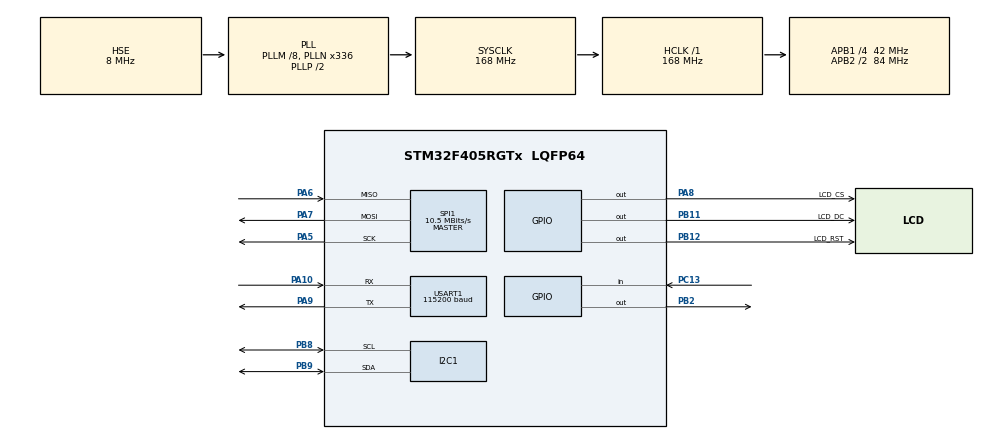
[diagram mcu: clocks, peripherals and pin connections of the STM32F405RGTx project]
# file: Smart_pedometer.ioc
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Dma.I2C1_RX.4.Direction=DMA_PERIPH_TO_MEMORY
Dma.I2C1_RX.4.FIFOMode=DMA_FIFOMODE_DISABLE
Dma.I2C1_RX.4.Instance=DMA1_Stream5
Dma.I2C1_RX.4.MemDataAlignment=DMA_MDATAALIGN_BYTE
Dma.I2C1_RX.4.MemInc=DMA_MINC_ENABLE
Dma.I2C1_RX.4.Mode=DMA_NORMAL
Dma.I2C1_RX.4.PeriphDataAlignment=DMA_PDATAALIGN_BYTE
Dma.I2C1_RX.4.PeriphInc=DMA_PINC_DISABLE
Dma.I2C1_RX.4.Priority=DMA_PRIORITY_LOW
Dma.I2C1_TX.5.Direction=DMA_MEMORY_TO_PERIPH
Dma.I2C1_TX.5.FIFOMode=DMA_FIFOMODE_DISABLE
Dma.I2C1_TX.5.Instance=DMA1_Stream6
Dma.I2C1_TX.5.MemDataAlignment=DMA_MDATAALIGN_BYTE
Dma.I2C1_TX.5.MemInc=DMA_MINC_ENABLE
Dma.I2C1_TX.5.Mode=DMA_NORMAL
Dma.I2C1_TX.5.PeriphDataAlignment=DMA_PDATAALIGN_BYTE
Dma.I2C1_TX.5.PeriphInc=DMA_PINC_DISABLE
Dma.I2C1_TX.5.Priority=DMA_PRIORITY_LOW
Dma.Request0=SPI1_RX
Dma.Request1=SPI1_TX
Dma.Request2=USART1_RX
Dma.Request3=USART1_TX
Dma.Request4=I2C1_RX
Dma.Request5=I2C1_TX
Dma.SPI1_RX.0.Direction=DMA_PERIPH_TO_MEMORY
Dma.SPI1_RX.0.FIFOMode=DMA_FIFOMODE_DISABLE
Dma.SPI1_RX.0.Instance=DMA2_Stream0
Dma.SPI1_RX.0.MemDataAlignment=DMA_MDATAALIGN_BYTE
Dma.SPI1_RX.0.MemInc=DMA_MINC_ENABLE
Dma.SPI1_RX.0.Mode=DMA_NORMAL
Dma.SPI1_RX.0.PeriphDataAlignment=DMA_PDATAALIGN_BYTE
Dma.SPI1_RX.0.PeriphInc=DMA_PINC_DISABLE
Dma.SPI1_RX.0.Priority=DMA_PRIORITY_LOW
Dma.SPI1_TX.1.Direction=DMA_MEMORY_TO_PERIPH
Dma.SPI1_TX.1.FIFOMode=DMA_FIFOMODE_DISABLE
Dma.SPI1_TX.1.Instance=DMA2_Stream3
Dma.SPI1_TX.1.MemDataAlignment=DMA_MDATAALIGN_BYTE
Dma.SPI1_TX.1.MemInc=DMA_MINC_ENABLE
Dma.SPI1_TX.1.Mode=DMA_NORMAL
Dma.SPI1_TX.1.PeriphDataAlignment=DMA_PDATAALIGN_BYTE
Dma.SPI1_TX.1.PeriphInc=DMA_PINC_DISABLE
Dma.SPI1_TX.1.Priority=DMA_PRIORITY_LOW
Dma.USART1_RX.2.Direction=DMA_PERIPH_TO_MEMORY
Dma.USART1_RX.2.FIFOMode=DMA_FIFOMODE_DISABLE
Dma.USART1_RX.2.Instance=DMA2_Stream2
Dma.USART1_RX.2.MemDataAlignment=DMA_MDATAALIGN_BYTE
Dma.USART1_RX.2.MemInc=DMA_MINC_ENABLE
Dma.USART1_RX.2.Mode=DMA_CIRCULAR
Dma.USART1_RX.2.PeriphDataAlignment=DMA_PDATAALIGN_BYTE
Dma.USART1_RX.2.PeriphInc=DMA_PINC_DISABLE
Dma.USART1_RX.2.Priority=DMA_PRIORITY_LOW
Dma.USART1_TX.3.Direction=DMA_MEMORY_TO_PERIPH
Dma.USART1_TX.3.FIFOMode=DMA_FIFOMODE_DISABLE
Dma.USART1_TX.3.Instance=DMA2_Stream7
Dma.USART1_TX.3.MemDataAlignment=DMA_MDATAALIGN_BYTE
Dma.USART1_TX.3.MemInc=DMA_MINC_ENABLE
Dma.USART1_TX.3.Mode=DMA_NORMAL
Dma.USART1_TX.3.PeriphDataAlignment=DMA_PDATAALIGN_BYTE
Dma.USART1_TX.3.PeriphInc=DMA_PINC_DISABLE
Dma.USART1_TX.3.Priority=DMA_PRIORITY_LOW
FREERTOS.Mutexes01=IIC_LOCK,Static,IIC_LOCKControlBlock,Available;SPI1_LOCK,Static,SPI1_LOCKControlBlock,Available;UART1_LOCK,Static,UART1_LOCKControlBlock,Available
FREERTOS.Queues01=KEY_EVT_Q,8,key_event_msg_t,0,Static,KEY_EVT_QBuffer,KEY_EVT_QControlBlock;UART_EVT_Q,4,dev_uart_t*,0,Static,UART_EVT_QBuffer,UART_EVT_QControlBlock
FREERTOS.Tasks01=defaultTask,8,128,StartDefaultTask,As weak,NULL,Static,defaultTaskBuffer,defaultTaskControlBlock;KEY_T,48,128,Task_Key_Scan,As weak,NULL,KEY_TBuffer,KEY_TControlBlock;KEY_CMD_T,40,256,Task_Key_Cmd,As weak,NULL,KEY_CMD_TBuffer,KEY_CMD_TControlBlock;LVGL_T,32,2048,Task_LVGL,As weak,NULL,LVGL_TBuffer,LVGL_TControlBlock;UART_T,24,256,Task_UART,As weak,NULL,UART_TBuffer,UART_TControlBlock
FREERTOS.configMINIMAL_STACK_SIZE=64
I2C1.I2C_Mode=I2C_Fast
Mcu.Family=STM32F4
Mcu.Name=STM32F405RGTx
Mcu.Package=LQFP64
NVIC.DMA1_Stream5_IRQn=true\:5\:0\:false\:false\:true\:true\:false\:true\:true
NVIC.DMA1_Stream6_IRQn=true\:5\:0\:false\:false\:true\:true\:false\:true\:true
NVIC.DMA2_Stream0_IRQn=true\:5\:0\:false\:false\:true\:true\:false\:true\:true
NVIC.DMA2_Stream2_IRQn=true\:5\:0\:false\:false\:true\:true\:false\:true\:true
NVIC.DMA2_Stream3_IRQn=true\:5\:0\:false\:false\:true\:true\:false\:true\:true
NVIC.DMA2_Stream7_IRQn=true\:5\:0\:false\:false\:true\:true\:false\:true\:true
NVIC.I2C1_ER_IRQn=true\:5\:0\:false\:false\:true\:true\:true\:true\:true
NVIC.I2C1_EV_IRQn=true\:5\:0\:false\:false\:true\:true\:true\:true\:true
NVIC.PriorityGroup=NVIC_PRIORITYGROUP_4
NVIC.SPI1_IRQn=true\:5\:0\:false\:false\:true\:true\:true\:true\:true
NVIC.TIM4_IRQn=true\:15\:0\:false\:false\:true\:false\:false\:true\:true
NVIC.TimeBase=TIM4_IRQn
NVIC.TimeBaseIP=TIM4
NVIC.USART1_IRQn=true\:5\:0\:false\:false\:true\:true\:true\:true\:true
PA10.Mode=Asynchronous
PA10.Signal=USART1_RX
PA13.Mode=Serial_Wire
PA13.Signal=SYS_JTMS-SWDIO
PA14.Mode=Serial_Wire
PA14.Signal=SYS_JTCK-SWCLK
PA5.Mode=Full_Duplex_Master
PA5.Signal=SPI1_SCK
PA6.Mode=Full_Duplex_Master
PA6.Signal=SPI1_MISO
PA7.Mode=Full_Duplex_Master
PA7.Signal=SPI1_MOSI
PA8.GPIO_Label=LCD_CS
PA8.GPIO_PuPd=GPIO_NOPULL
PA8.GPIO_Speed=GPIO_SPEED_FREQ_HIGH
PA8.PinState=GPIO_PIN_SET
PA8.Signal=GPIO_Output
PA9.Mode=Asynchronous
PA9.Signal=USART1_TX
PB11.GPIO_Label=LCD_DC
PB11.GPIO_ModeDefaultOutputPP=GPIO_MODE_OUTPUT_PP
PB11.GPIO_PuPd=GPIO_NOPULL
PB11.GPIO_Speed=GPIO_SPEED_FREQ_HIGH
PB11.PinState=GPIO_PIN_RESET
PB11.Signal=GPIO_Output
PB12.GPIO_Label=LCD_RST
PB12.GPIO_PuPd=GPIO_NOPULL
PB12.GPIO_Speed=GPIO_SPEED_FREQ_HIGH
PB12.PinState=GPIO_PIN_SET
PB12.Signal=GPIO_Output
PB2.GPIO_PuPd=GPIO_PULLDOWN
PB2.PinState=GPIO_PIN_RESET
PB2.Signal=GPIO_Output
PB8.Mode=I2C
PB8.Signal=I2C1_SCL
PB9.Mode=I2C
PB9.Signal=I2C1_SDA
PC13-ANTI_TAMP.GPIO_Mode=GPIO_MODE_INPUT
PC13-ANTI_TAMP.GPIO_PuPd=GPIO_PULLDOWN
PC13-ANTI_TAMP.Signal=GPIO_Input
PH0-OSC_IN.Mode=HSE-External-Oscillator
PH0-OSC_IN.Signal=RCC_OSC_IN
PH1-OSC_OUT.Mode=HSE-External-Oscillator
PH1-OSC_OUT.Signal=RCC_OSC_OUT
ProjectManager.HeapSize=0x200
ProjectManager.StackSize=0x400
ProjectManager.TargetToolchain=CMake
RCC.AHBFreq_Value=168000000
RCC.APB1CLKDivider=RCC_HCLK_DIV4
RCC.APB1Freq_Value=42000000
RCC.APB1TimFreq_Value=84000000
RCC.APB2CLKDivider=RCC_HCLK_DIV2
RCC.APB2Freq_Value=84000000
RCC.APB2TimFreq_Value=168000000
RCC.CortexFreq_Value=168000000
RCC.HCLKFreq_Value=168000000
RCC.HSE_VALUE=8000000
RCC.HSI_VALUE=16000000
RCC.LSE_VALUE=32768
RCC.PLLM=8
RCC.PLLN=336
RCC.PLLP=RCC_PLLP_DIV2
RCC.PLLQ=7
RCC.PLLSourceVirtual=RCC_PLLSOURCE_HSE
RCC.SYSCLKFreq_VALUE=168000000
RCC.SYSCLKSource=RCC_SYSCLKSOURCE_PLLCLK
RCC.VCOOutputFreq_Value=336000000
SPI1.BaudRatePrescaler=SPI_BAUDRATEPRESCALER_8
SPI1.CalculateBaudRate=10.5 MBits/s
SPI1.Direction=SPI_DIRECTION_2LINES
SPI1.Mode=SPI_MODE_MASTER
SPI1.VirtualType=VM_MASTER
USART1.BaudRate=115200
USART1.VirtualMode=VM_ASYNC
VP_CRC_VS_CRC.Mode=CRC_Activate
VP_FREERTOS_VS_CMSIS_V2.Mode=CMSIS_V2
VP_SYS_VS_tim4.Mode=TIM4
board=custom

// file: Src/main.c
/* USER CODE BEGIN Header */
/**
  ******************************************************************************
  * @file           : main.c
  * @brief          : Main program body
  ******************************************************************************
  * @attention
  *
  * Copyright (c) 2026 STMicroelectronics.
  * All rights reserved.
  *
  * This software is licensed under terms that can be found in the LICENSE file
  * in the root directory of this software component.
  * If no LICENSE file comes with this software, it is provided AS-IS.
  *
  ******************************************************************************
  */
/* USER CODE END Header */
#include "main.h"
#include "cmsis_os.h"
#include "crc.h"
#include "dma.h"
#include "i2c.h"
#include "spi.h"
#include "usart.h"
#include "gpio.h"

void SystemClock_Config(void);
void MX_FREERTOS_Init(void);

int main(void)
{

  /* MCU Configuration--------------------------------------------------------*/

  /* Reset of all peripherals, Initializes the Flash interface and the Systick. */
  HAL_Init();

  /* Configure the system clock */
  SystemClock_Config();

  /* Initialize all configured peripherals */
  MX_GPIO_Init();
  MX_DMA_Init();
  MX_CRC_Init();
  MX_I2C1_Init();
  MX_SPI1_Init();
  MX_USART1_UART_Init();

  /* Init scheduler */
  osKernelInitialize();  /* Call init function for freertos objects (in cmsis_os2.c) */
  MX_FREERTOS_Init();

  /* Start scheduler */
  osKernelStart();

  /* We should never get here as control is now taken by the scheduler */

  /* Infinite loop */
  while (1)
  {

  }
}

void SystemClock_Config(void)
{
  RCC_OscInitTypeDef RCC_OscInitStruct = {0};
  RCC_ClkInitTypeDef RCC_ClkInitStruct = {0};

  /** Configure the main internal regulator output voltage
  */
  __HAL_RCC_PWR_CLK_ENABLE();
  __HAL_PWR_VOLTAGESCALING_CONFIG(PWR_REGULATOR_VOLTAGE_SCALE1);

  /** Initializes the RCC Oscillators according to the specified parameters
  * in the RCC_OscInitTypeDef structure.
  */
  RCC_OscInitStruct.OscillatorType = RCC_OSCILLATORTYPE_HSE;
  RCC_OscInitStruct.HSEState = RCC_HSE_ON;
  RCC_OscInitStruct.PLL.PLLState = RCC_PLL_ON;
  RCC_OscInitStruct.PLL.PLLSource = RCC_PLLSOURCE_HSE;
  RCC_OscInitStruct.PLL.PLLM = 8;
  RCC_OscInitStruct.PLL.PLLN = 336;
  RCC_OscInitStruct.PLL.PLLP = RCC_PLLP_DIV2;
  RCC_OscInitStruct.PLL.PLLQ = 7;
  if (HAL_RCC_OscConfig(&RCC_OscInitStruct) != HAL_OK)
  {
    Error_Handler();
  }

  /** Initializes the CPU, AHB and APB buses clocks
  */
  RCC_ClkInitStruct.ClockType = RCC_CLOCKTYPE_HCLK|RCC_CLOCKTYPE_SYSCLK
                              |RCC_CLOCKTYPE_PCLK1|RCC_CLOCKTYPE_PCLK2;
  RCC_ClkInitStruct.SYSCLKSource = RCC_SYSCLKSOURCE_PLLCLK;
  RCC_ClkInitStruct.AHBCLKDivider = RCC_SYSCLK_DIV1;
  RCC_ClkInitStruct.APB1CLKDivider = RCC_HCLK_DIV4;
  RCC_ClkInitStruct.APB2CLKDivider = RCC_HCLK_DIV2;

  if (HAL_RCC_ClockConfig(&RCC_ClkInitStruct, FLASH_LATENCY_5) != HAL_OK)
  {
    Error_Handler();
  }
}

void HAL_TIM_PeriodElapsedCallback(TIM_HandleTypeDef *htim)
{
  if (htim->Instance == TIM4)
  {
    HAL_IncTick();
  }
}

void Error_Handler(void)
{
  __disable_irq();
  while (1)
  {
  }
}

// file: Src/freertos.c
/* USER CODE BEGIN Header */
/**
  ******************************************************************************
  * File Name          : freertos.c
  * Description        : Code for freertos applications
  ******************************************************************************
  * @attention
  *
  * Copyright (c) 2026 STMicroelectronics.
  * All rights reserved.
  *
  * This software is licensed under terms that can be found in the LICENSE file
  * in the root directory of this software component.
  * If no LICENSE file comes with this software, it is provided AS-IS.
  *
  ******************************************************************************
  */
/* USER CODE END Header */

#include "FreeRTOS.h"
#include "task.h"
#include "main.h"
#include "cmsis_os.h"

/* USER CODE BEGIN Includes */
#include "osal_types.h"
#include "bsp_iic.h"
#include "bsp_spi.h"
#include "dev_spi.h"
#include "dev_iic.h"
/* USER CODE END Includes */

typedef StaticTask_t osStaticThreadDef_t;
typedef StaticQueue_t osStaticMessageQDef_t;
typedef StaticSemaphore_t osStaticMutexDef_t;

/* Definitions for defaultTask */
osThreadId_t defaultTaskHandle;
uint32_t defaultTaskBuffer[ 128 ];
osStaticThreadDef_t defaultTaskControlBlock;
const osThreadAttr_t defaultTask_attributes = {
  .name = "defaultTask",
  .cb_mem = &defaultTaskControlBlock,
  .cb_size = sizeof(defaultTaskControlBlock),
  .stack_mem = &defaultTaskBuffer[0],
  .stack_size = sizeof(defaultTaskBuffer),
  .priority = (osPriority_t) osPriorityLow,
};
/* Definitions for KEY_T */
osThreadId_t KEY_THandle;
const osThreadAttr_t KEY_T_attributes = {
  .name = "KEY_T",
  .stack_size = 128 * 4,
  .priority = (osPriority_t) osPriorityRealtime,
};
/* Definitions for KEY_CMD_T */
osThreadId_t KEY_CMD_THandle;
const osThreadAttr_t KEY_CMD_T_attributes = {
  .name = "KEY_CMD_T",
  .stack_size = 256 * 4,
  .priority = (osPriority_t) osPriorityHigh,
};
/* Definitions for LVGL_T */
osThreadId_t LVGL_THandle;
const osThreadAttr_t LVGL_T_attributes = {
  .name = "LVGL_T",
  .stack_size = 2048 * 4,
  .priority = (osPriority_t) osPriorityAboveNormal,
};
/* Definitions for UART_T */
osThreadId_t UART_THandle;
const osThreadAttr_t UART_T_attributes = {
  .name = "UART_T",
  .stack_size = 256 * 4,
  .priority = (osPriority_t) osPriorityNormal,
};
/* Definitions for KEY_EVT_Q */
osMessageQueueId_t KEY_EVT_QHandle;
uint8_t KEY_EVT_QBuffer[ 8 * sizeof( key_event_msg_t ) ];
osStaticMessageQDef_t KEY_EVT_QControlBlock;
const osMessageQueueAttr_t KEY_EVT_Q_attributes = {
  .name = "KEY_EVT_Q",
  .cb_mem = &KEY_EVT_QControlBlock,
  .cb_size = sizeof(KEY_EVT_QControlBlock),
  .mq_mem = &KEY_EVT_QBuffer,
  .mq_size = sizeof(KEY_EVT_QBuffer)
};
/* Definitions for UART_EVT_Q */
osMessageQueueId_t UART_EVT_QHandle;
uint8_t UART_EVT_QBuffer[ 4 * sizeof( dev_uart_t* ) ];
osStaticMessageQDef_t UART_EVT_QControlBlock;
const osMessageQueueAttr_t UART_EVT_Q_attributes = {
  .name = "UART_EVT_Q",
  .cb_mem = &UART_EVT_QControlBlock,
  .cb_size = sizeof(UART_EVT_QControlBlock),
  .mq_mem = &UART_EVT_QBuffer,
  .mq_size = sizeof(UART_EVT_QBuffer)
};
/* Definitions for IIC_LOCK */
osMutexId_t IIC_LOCKHandle;
osStaticMutexDef_t IIC_LOCKControlBlock;
const osMutexAttr_t IIC_LOCK_attributes = {
  .name = "IIC_LOCK",
  .cb_mem = &IIC_LOCKControlBlock,
  .cb_size = sizeof(IIC_LOCKControlBlock),
};
/* Definitions for SPI1_LOCK */
osMutexId_t SPI1_LOCKHandle;
osStaticMutexDef_t SPI1_LOCKControlBlock;
const osMutexAttr_t SPI1_LOCK_attributes = {
  .name = "SPI1_LOCK",
  .cb_mem = &SPI1_LOCKControlBlock,
  .cb_size = sizeof(SPI1_LOCKControlBlock),
};
/* Definitions for UART1_LOCK */
osMutexId_t UART1_LOCKHandle;
osStaticMutexDef_t UART1_LOCKControlBlock;
const osMutexAttr_t UART1_LOCK_attributes = {
  .name = "UART1_LOCK",
  .cb_mem = &UART1_LOCKControlBlock,
  .cb_size = sizeof(UART1_LOCKControlBlock),
};

void StartDefaultTask(void *argument);
void Task_Key_Scan(void *argument);
void Task_Key_Cmd(void *argument);
void Task_LVGL(void *argument);
void Task_UART(void *argument);

void MX_FREERTOS_Init(void); /* (MISRA C 2004 rule 8.1) */

void MX_FREERTOS_Init(void) {
  /* USER CODE BEGIN Init */
  Svc_Key_Logic_Init();   /* 以当前键电平作为"已确认"初态，避免上电误报 DOWN */
  /* USER CODE END Init */
  /* Create the mutex(es) */
  /* creation of IIC_LOCK */
  IIC_LOCKHandle = osMutexNew(&IIC_LOCK_attributes);

  /* creation of SPI1_LOCK */
  SPI1_LOCKHandle = osMutexNew(&SPI1_LOCK_attributes);

  /* creation of UART1_LOCK */
  UART1_LOCKHandle = osMutexNew(&UART1_LOCK_attributes);

  /* USER CODE BEGIN RTOS_MUTEX */
  /* 要互斥量的 BSP 初始化必须在这里：CubeMX 刚把这几把锁建出来，
   早一段（Init）句柄还是 NULL，会被 BSP_xxx_Init() 判成 ERR_STATE。
   设备层的虚拟外设跟在对应 BSP 总线之后：Dev_SPI / Dev_IIC 各自认领
   SPI1 / IIC 这把锁，并把片选、换速、超时这些"总线使用规则"接在
   BSP_SPI / BSP_IIC 之上。 */
  BSP_IIC_Init();
  Dev_IIC_Init(&dev_iic1);
  BSP_SPI_Init();
  Dev_SPI_Init(&dev_spi1);
  /* USER CODE END RTOS_MUTEX */

  /* Create the queue(s) */
  /* creation of KEY_EVT_Q */
  KEY_EVT_QHandle = osMessageQueueNew (8, sizeof(key_event_msg_t), &KEY_EVT_Q_attributes);

  /* creation of UART_EVT_Q */
  UART_EVT_QHandle = osMessageQueueNew (4, sizeof(dev_uart_t*), &UART_EVT_Q_attributes);

  /* USER CODE BEGIN RTOS_QUEUES */
  /* UART 的接收事件投在 CubeMX 刚建好的 UART_EVT_Q 里，所以武装 DMA 必须
     放到建队之后：建队前来的字节没有队列可投，事件会丢。发送互斥量在上面
     已经建好，Dev_UART_Write 可以直接用 UART1_LOCK。 */
  Dev_UART_Init(&dev_uart1);
  /* USER CODE END RTOS_QUEUES */

  /* Create the thread(s) */
  /* creation of defaultTask */
  defaultTaskHandle = osThreadNew(StartDefaultTask, NULL, &defaultTask_attributes);

  /* creation of KEY_T */
  KEY_THandle = osThreadNew(Task_Key_Scan, NULL, &KEY_T_attributes);

  /* creation of KEY_CMD_T */
  KEY_CMD_THandle = osThreadNew(Task_Key_Cmd, NULL, &KEY_CMD_T_attributes);

  /* creation of LVGL_T */
  LVGL_THandle = osThreadNew(Task_LVGL, NULL, &LVGL_T_attributes);

  /* creation of UART_T */
  UART_THandle = osThreadNew(Task_UART, NULL, &UART_T_attributes);

}

__weak void StartDefaultTask(void *argument)
{
  for(;;)
  {
    osDelay(1);
  }
}

__weak void Task_Key_Scan(void *argument)
{
  for(;;)
  {
    osDelay(1);
  }
}

__weak void Task_Key_Cmd(void *argument)
{
  for(;;)
  {
    osDelay(1);
  }
}

__weak void Task_LVGL(void *argument)
{
  for(;;)
  {
    osDelay(1);
  }
}

__weak void Task_UART(void *argument)
{
  for(;;)
  {
    osDelay(1);
  }
}
